# ICSSM0_COMMON_0_PR1_PDSP1_IRAM register map
Vendor: Texas Instruments
Peripheral module from a debugger description file (folder am62x).
Registers are 32-bit, read-write, reset 0x0 unless marked. A register's access mark holds for its fields unless they carry their own. Offsets are as the file gives them; lines under a group give offsets from that group; [hi:lo] are bit positions; {n}, {i} and the like mark numbered series; 'fields as' and 'values as' point back to an identical list; <NAME> marks a mode.

## ICSSM0_COMMON_0_PR1_PDSP1_IRAM
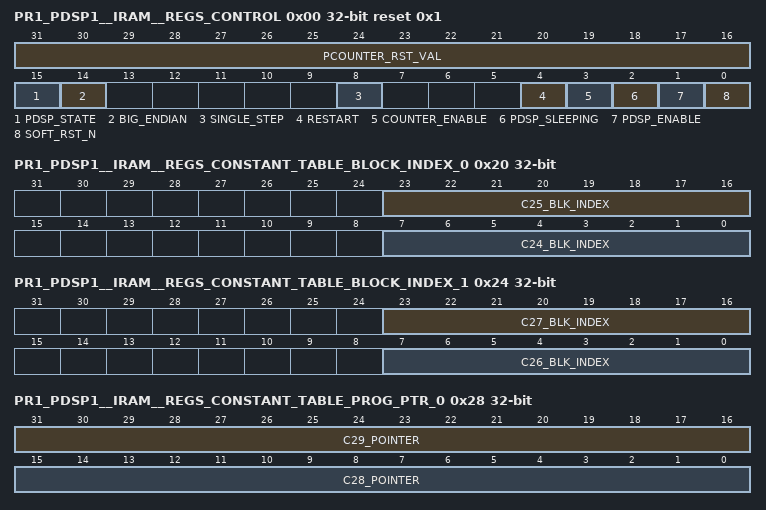
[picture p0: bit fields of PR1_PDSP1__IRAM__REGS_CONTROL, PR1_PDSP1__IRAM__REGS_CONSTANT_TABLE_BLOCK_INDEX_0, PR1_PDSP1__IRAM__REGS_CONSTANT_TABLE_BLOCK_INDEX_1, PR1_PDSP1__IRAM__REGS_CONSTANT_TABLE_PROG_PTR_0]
0x00 PR1_PDSP1__IRAM__REGS_CONTROL access per field reset 0x1
  [31:16] PCOUNTER_RST_VAL rw — Program counter reset value
  [15] PDSP_STATE ro — PDSP run state: 0=PDSP is halted, 1=PDSP is running
  [14] BIG_ENDIAN ro — Big-endian input state
  [8] SINGLE_STEP rw — Single step enable: 0=PDSP will free run when enabled, 1=PDSP will execute a single instruction and then the pdsp_enable bit will be cleared
  [4] RESTART rw — Causes PDSP to stop current operation gracefully and return to the PC reset value
  [3] COUNTER_ENABLE rw — PDSP cycle counter enable: 0=Counters not enabled, 1=Counters enabled
  [2] PDSP_SLEEPING rw — PDSP sleep indicator: 0=PDSP is not asleep, 1=PDSP us asleep
  [1] PDSP_ENABLE rw — PDSP enable: 0=PDSP is disabled, 1=PDSP is enabled
  [0] SOFT_RST_N ro — Soft reset. When this bit is cleared, the PDSP will be reset. This bit is set back to 1 on the next cycle after it has been cleared.
0x04 PR1_PDSP1__IRAM__REGS_STATUS ro
  [15:0] PCOUNTER — Current PDSP program counter
0x08 PR1_PDSP1__IRAM__REGS_WAKEUP_ENABLE
  [31:0] BITWISE_ENABLES — Wakeup enables
0x0C PR1_PDSP1__IRAM__REGS_CYCLE_COUNT
  [31:0] CYCLECOUNT — This value is incremented by 1 for every clock cycle during which the PDSP is enabled and the counter is enabled.
0x10 PR1_PDSP1__IRAM__REGS_STALL_COUNT ro
  [31:0] STALLCOUNT — This value is incremented by 1 for every clock cycle during which the PDSP is enabled, the counter is enabled, and the PDSP was unable to fetch a new instruction for any reason.
0x20 PR1_PDSP1__IRAM__REGS_CONSTANT_TABLE_BLOCK_INDEX_0
  [23:16] C25_BLK_INDEX — PDSP constant entry 25 block index
  [7:0] C24_BLK_INDEX — PDSP constant entry 24 block index
0x24 PR1_PDSP1__IRAM__REGS_CONSTANT_TABLE_BLOCK_INDEX_1
  [23:16] C27_BLK_INDEX — PDSP constant entry 27 block index
  [7:0] C26_BLK_INDEX — PDSP constant entry 26 block index
0x28 PR1_PDSP1__IRAM__REGS_CONSTANT_TABLE_PROG_PTR_0
  [31:16] C29_POINTER — PDSP constant entry 29 pointer
  [15:0] C28_POINTER — PDSP constant entry 28 pointer
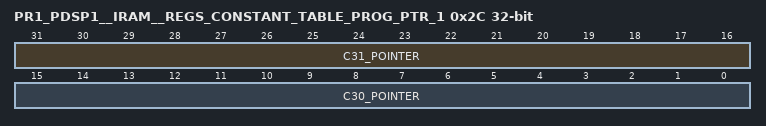
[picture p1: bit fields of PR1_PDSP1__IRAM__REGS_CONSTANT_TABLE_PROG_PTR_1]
0x2C PR1_PDSP1__IRAM__REGS_CONSTANT_TABLE_PROG_PTR_1
  [31:16] C31_POINTER — PDSP constant entry 31 pointer
  [15:0] C30_POINTER — PDSP constant entry 30 pointer
